# MSP430FR4133 register map
Registers are 16-bit, read-write, reset 0x0 unless marked. A register's access mark holds for its fields unless they carry their own. Offsets are from the block's base; [hi:lo] are bit positions; {n}, {i} and the like mark numbered series.

## USCI_B0_SPI_MODE
Base 0x00000540
0x00 UCB0CTL1_SPI 8-bit — USCI B0 Control Register 1
0x01 UCB0CTL0_SPI 8-bit — USCI B0 Control Register 0
0x06 UCB0BR0_SPI 8-bit — USCI B0 Baud Rate 0
0x07 UCB0BR1_SPI 8-bit — USCI B0 Baud Rate 1
0x0C UCB0RXBUF_SPI — USCI B0 Receive Buffer
0x0E UCB0TXBUF_SPI — USCI B0 Transmit Buffer
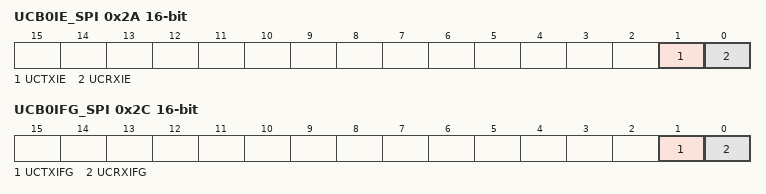
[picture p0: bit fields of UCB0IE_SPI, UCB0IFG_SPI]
0x2A UCB0IE_SPI — USCI B0 Interrupt Enable Register
  [1] UCTXIE — USCI Transmit Interrupt Enable
  [0] UCRXIE — USCI Receive Interrupt Enable
0x2C UCB0IFG_SPI — USCI B0 Interrupt Flags Register
  [1] UCTXIFG — SPI Transmit Interrupt Flag
  [0] UCRXIFG — SPI Receive Interrupt Flag
0x2E UCB0IV_SPI — USCI B0 Interrupt Vector Register

## SFR — SFR Special Function Registers
Base 0x00000100
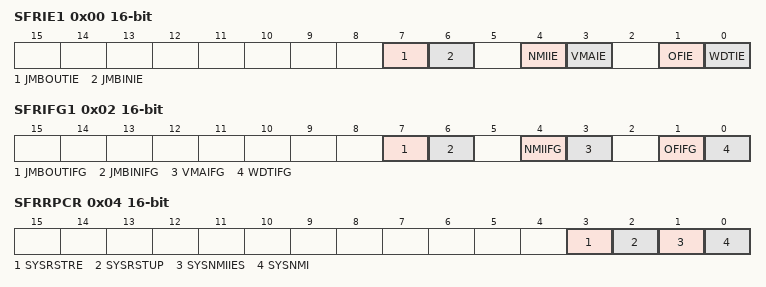
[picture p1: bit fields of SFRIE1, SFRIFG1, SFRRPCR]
0x00 SFRIE1 — Interrupt Enable 1
  [7] JMBOUTIE — JTAG Mail Box output Interrupt Enable
  [6] JMBINIE — JTAG Mail Box input Interrupt Enable
  [4] NMIIE — NMI Interrupt Enable
  [3] VMAIE — Vacant Memory Interrupt Enable
  [1] OFIE — Osc Fault Enable
  [0] WDTIE — WDT Interrupt Enable
0x02 SFRIFG1 — Interrupt Flag 1
  [7] JMBOUTIFG — JTAG Mail Box output Interrupt Flag
  [6] JMBINIFG — JTAG Mail Box input Interrupt Flag
  [4] NMIIFG — NMI Interrupt Flag
  [3] VMAIFG — Vacant Memory Interrupt Flag
  [1] OFIFG — Osc Fault Flag
  [0] WDTIFG — WDT Interrupt Flag
0x04 SFRRPCR — RESET Pin Control Register
  [3] SYSRSTRE — RESET Pin Resistor enable
  [2] SYSRSTUP — RESET Pin pull down/up select
  [1] SYSNMIIES — NMI edge select
  [0] SYSNMI — NMI select

## PMM — PMM Power Management System
Base 0x00000120
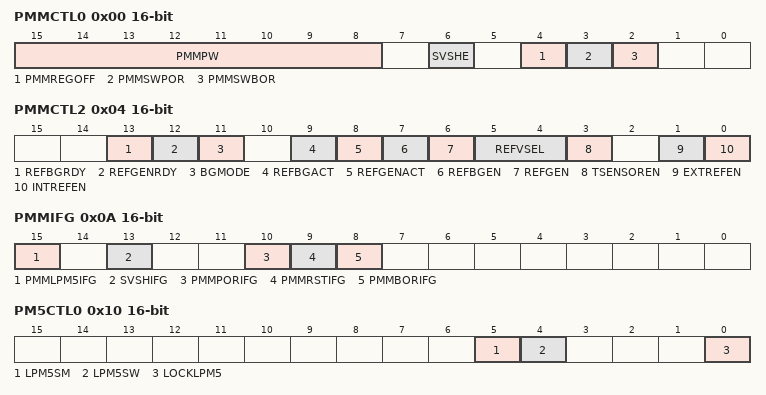
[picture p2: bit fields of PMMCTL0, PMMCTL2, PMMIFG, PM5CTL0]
0x00 PMMCTL0 — PMM Control 0
  [15:8] PMMPW — PMM Password
    on read: 150=PASSWORD (Values always reads from the PMMCTL0 register) | on write: 165=PASSWORD (Values which must be written to the PMMCTL0 register)
  [6] SVSHE — SVS high side enable
  [4] PMMREGOFF — PMM Turn Regulator off
  [3] PMMSWPOR — PMM Software POR
  [2] PMMSWBOR — PMM Software BOR
0x02 PMMCTL1 — PMM Control 1
0x04 PMMCTL2 — PMM Control 2
  [13] REFBGRDY — REF Reference bandgap ready
  [12] REFGENRDY — REF Reference generator ready
  [11] BGMODE — REF Bandgap mode
  [9] REFBGACT — REF Reference bandgap active
  [8] REFGENACT — REF Reference generator active
  [7] REFBGEN — Bandgap and bandgap buffer trigger. If written with a 1, the generation of the buffered bandgap voltage is started. When the bandgap buffer voltage request is set, this bit is cleared by hardware or writing 0.
  [6] REFGEN — Reference generator trigger. If written with a 1, the generation of the variable reference voltage is started. When the reference voltage request is set, this bit is cleared by hardware or writing 0.
  [5:4] REFVSEL — Internal reference voltage level select. 00b = 1.5V, 01b = 2.0V, 10b = 2.5V
    0=00b = 1.5V; 1=01b = 2.0V; 2=10b = 2.5V; 3=11b = Reserved
  [3] TSENSOREN — Temperature Sensor Enable
  [1] EXTREFEN — External Reference output Enable
  [0] INTREFEN — Internal Reference Enable
0x0A PMMIFG — PMM Interrupt Flag
  [15] PMMLPM5IFG — LPM5 indication Flag
  [13] SVSHIFG — SVS low side interrupt flag
  [10] PMMPORIFG — PMM Software POR interrupt flag
  [9] PMMRSTIFG — PMM RESET pin interrupt flag
  [8] PMMBORIFG — PMM Software BOR interrupt flag
0x0E PMMIE — PMM Interrupt Enable
0x10 PM5CTL0 — PMM Power Mode 5 Control Register 0
  [5] LPM5SM — Manual mode for LPM3.5 switch
  [4] LPM5SW — LPMx.5 switch dis/connected
  [0] LOCKLPM5 — Lock I/O pin configuration upon entry/exit to/from LPM5

## SYS — SYS System Module
Base 0x00000140
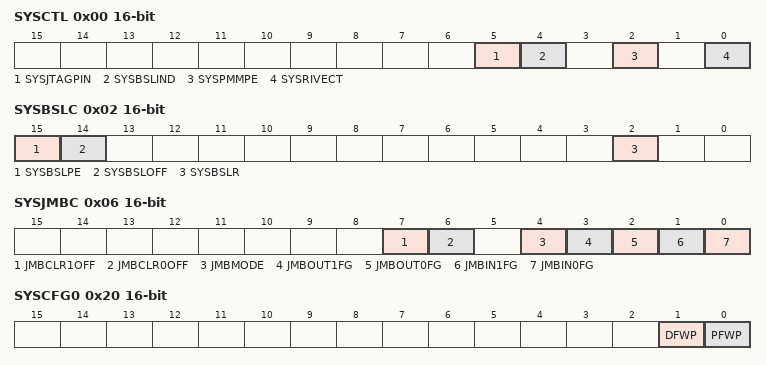
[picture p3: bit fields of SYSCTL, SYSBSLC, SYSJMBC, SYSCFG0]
0x00 SYSCTL — System control
  [5] SYSJTAGPIN — SYS - Dedicated JTAG pins enabled
  [4] SYSBSLIND — SYS - TCK/RST indication detected
  [2] SYSPMMPE — SYS - PMM access protect
  [0] SYSRIVECT — SYS - RAM based interrupt vectors
0x02 SYSBSLC — Boot strap configuration area
  [15] SYSBSLPE — SYS - BSL Memory protection enabled
  [14] SYSBSLOFF — SYS - BSL Memory disabled
  [2] SYSBSLR — SYS - RAM assigned to BSL
0x06 SYSJMBC — JTAG mailbox control
  [7] JMBCLR1OFF — SYS - Incoming JTAG Mailbox 1 Flag auto-clear disalbe
  [6] JMBCLR0OFF — SYS - Incoming JTAG Mailbox 0 Flag auto-clear disalbe
  [4] JMBMODE — SYS - JMB 16/32 Bit Mode
  [3] JMBOUT1FG — SYS - Outgoing JTAG Mailbox 1 Flag
  [2] JMBOUT0FG — SYS - Outgoing JTAG Mailbox 0 Flag
  [1] JMBIN1FG — SYS - Incoming JTAG Mailbox 1 Flag
  [0] JMBIN0FG — SYS - Incoming JTAG Mailbox 0 Flag
0x08 SYSJMBI0 — JTAG mailbox input 0
0x0A SYSJMBI1 — JTAG mailbox input 1
0x0C SYSJMBO0 — JTAG mailbox output 0
0x0E SYSJMBO1 — JTAG mailbox output 1
0x18 SYSBERRIV — Bus Error vector generator
0x1A SYSUNIV — User NMI vector generator
0x1C SYSSNIV — System NMI vector generator
0x1E SYSRSTIV — Reset vector generator
0x20 SYSCFG0 — System Configuration 0
  [1] DFWP — Data FRAM Write Protection
  [0] PFWP — Program FRAM Write Protection
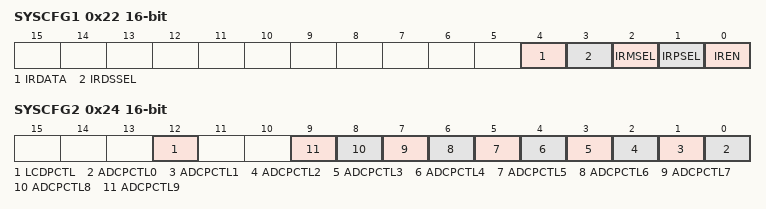
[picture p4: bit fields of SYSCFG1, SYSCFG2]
0x22 SYSCFG1 — System Configuration 1
  [4] IRDATA — Infrared enable
  [3] IRDSSEL — Infrared data source select
  [2] IRMSEL — Infrared mode select
  [1] IRPSEL — Infrared polarity select
  [0] IREN — Infrared enable
0x24 SYSCFG2 — System Configuration 2
  [12] LCDPCTL — LCD Power Pin
  [n] ADCPCTL{n} (n=0..9) — ADC input A{n} pin select
